# XN11EXXX register map
File version: 1.3
CPU: CM0 r0p0, little endian, no MPU, no FPU, 2 interrupt priority bits
Registers are 32-bit, read-write, reset 0x0 unless marked. A register's access mark holds for its fields unless they carry their own. Offsets are from the block's base; [hi:lo] are bit positions; {n}, {i} and the like mark numbered series.

## PWM — Pulse-Width Modulation
Base 0x4004C000
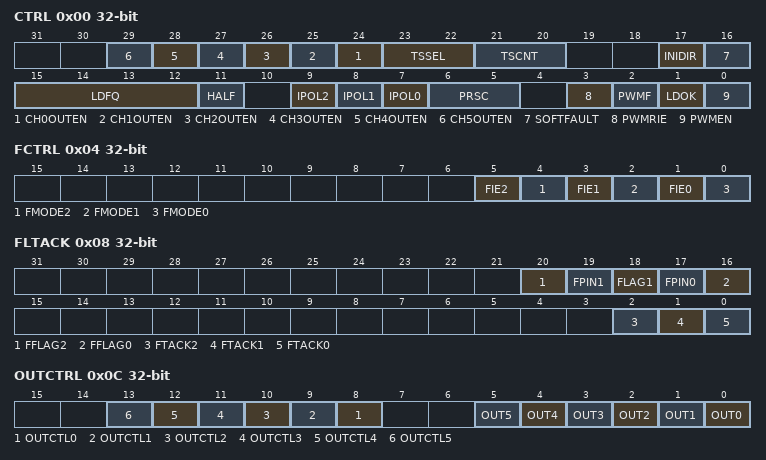
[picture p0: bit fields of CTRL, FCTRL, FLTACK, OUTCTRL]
0x00 CTRL — Control Register
  [n+24] CH{n}OUTEN (n=0..5) — Output a signal when counter register of channel {n} equals to VAL{n}
  [23:22] TSSEL — Trig signal select register
  [21:20] TSCNT — Trig signal output count register
  [17] INIDIR — Select initial count direction in center align mode
  [16] SOFTFAULT — trigger a software fault to the PWM Fault protect mode
  [15:12] LDFQ — select the PWM load frequency
  [11] HALF — Enable half-cycle reloads in Center-Aligned PWM mode
  [9] IPOL2 — Select the PWM value register for the PWM_4 and PWM_5 pins pair in complementary mode.
  [8] IPOL1 — Select the PWM value register for the PWM_2 and PWM_3 pins pair in complementary mode.
  [7] IPOL0 — Select the PWM value register for the PWM_0 and PWM_1 pins pair in complementary mode
  [6:5] PRSC — PWM clock Pre frequency set bit
  [3] PWMRIE — PWMF interrupt control bit
  [2] PWMF — PWM reload flag bit
  [1] LDOK — Load vaule bit
  [0] PWMEN — PWM enable
0x04 FCTRL — Fault Control Register
  [5] FIE2 — Enable the interrupt request generated by the ADC limit fault
  [4] FMODE2 — Select automatic or manual clearing of ADC limit faults
  [3] FIE1 — Enable the interrupt request generated by the Software fault
  [2] FMODE1 — Select automatic or manual clearing of Software faults
  [1] FIE0 — Enable the interrupt request generated by the PWM_FAULT0 pin
  [0] FMODE0 — Select automatic or manual clearing of FAULT0 pin faults
0x08 FLTACK — Fault Status/Acknowledge Register
  [20] FFLAG2 — SOFTFAULT flag
  [19] FPIN1 — ADC limit fault state
  [18] FLAG1 — ADC limit fault flag
  [17] FPIN0 — PWM_FAULT pin state
  [16] FFLAG0 — PWM_FAULT pin fault flag
  [2] FTACK2 — Software error Acknowledge,Writing a Logic 1 to FTACK2 clears FFLAG2
  [1] FTACK1 — ADC limit error Acknowledge,Writing a Logic 1 to FTACK1 clears FFLAG1.
  [0] FTACK0 — PWM_FAULT pin error Acknowledge,Writing a Logic 1 to FTACK0 clears FFLAG0.
0x0C OUTCTRL — Output Control Register
  [n+8] OUTCTL{n} (n=0..5) — Software control enable to PWM_{n}
  [n] OUT{n} (n=0..5) — PWM_{n} control
0x10 CNTR ro — Counter Register
  [15:0] CNT — 16-bit PWM counter
0x14 CMOD — Counter Modulo Register
  [15:0] CM — PWM Counter Modulo value
{0x18+4i} VAL{i} (i=0..5) — Value Register {i}
  [15:0] VAL — PWM value
0x38 DTIM0 reset 0xFFF — Deadtime Register 0
  [15:0] DTIM — deadtime during 0 to 1 transitions
0x3C DTIM1 reset 0xFFF — Deadtime Register 1
  [15:0] DTIM — deadtime during 1 to 0 transitions
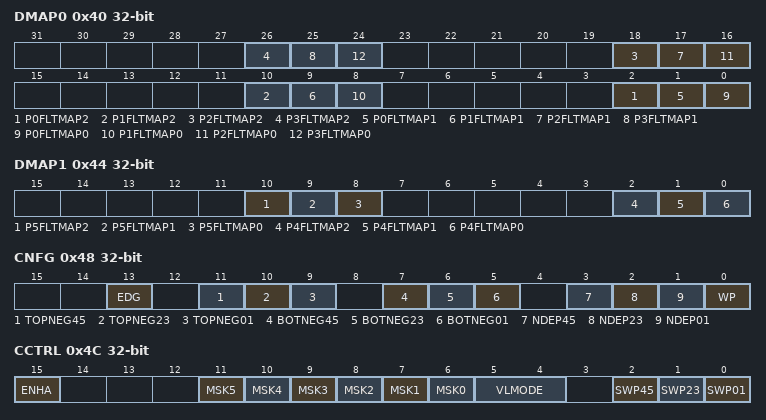
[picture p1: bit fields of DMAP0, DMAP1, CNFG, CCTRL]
0x40 DMAP0 — Disable Mapping Register0
  [8n+2] P{n}FLTMAP2 (n=0..3) — Enables ADC out of limit to protect PWM pin 0 output
  [8n+1] P{n}FLTMAP1 (n=0..3) — Enables Software Fault to protect PWM pin 0 output
  [8n] P{n}FLTMAP0 (n=0..3) — Enables Fault pin 0 to protect PWM pin 0 output
0x44 DMAP1 — Disable Mapping Register1
  [10] P5FLTMAP2 — Enables ADC out of limit to protect PWM pin 0 output
  [9] P5FLTMAP1 — Enables Software Fault to protect PWM pin 0 output
  [8] P5FLTMAP0 — Enables Fault pin 0 to protect PWM pin 0 output
  [2] P4FLTMAP2 — Enables ADC out of limit to protect PWM pin 0 output
  [1] P4FLTMAP1 — Enables Software Fault to protect PWM pin 0 output
  [0] P4FLTMAP0 — Enables Fault pin 0 to protect PWM pin 0 output
0x48 CNFG — Configure Register
  [13] EDG — Edge-Aligned or Center-Aligned wave forms selection
  [11] TOPNEG45 — polarity for the top-side PWMs selection
  [10] TOPNEG23 — polarity for the top-side PWMs selection
  [9] TOPNEG01 — polarity for the top-side PWMs selection
  [7] BOTNEG45 — polarity for the bottom-side PWMs selection
  [6] BOTNEG23 — polarity for the bottom-side PWMs selection
  [5] BOTNEG01 — polarity for the bottom-side PWMs selection
  [3] NDEP45 — independent PWMs or complementary PWM pairs selection
  [2] NDEP23 — independent PWMs or complementary PWM pairs selection
  [1] NDEP01 — independent PWMs or complementary PWM pairs selection
  [0] WP — Enables write-protection for all write-protectable registers
0x4C CCTRL — Channel Control Register
  [15] ENHA — Enable Hardware Acceleration
  [n+6] MSK{n} (n=0..5) — The mask of the PWM logical channel {n}
  [5:4] VLMODE — To be filled
  [2] SWP45 — This bit is write-protected when ENHA is zero
  [1] SWP23 — This bit is write-protected when ENHA is zero
  [0] SWP01 — This bit is write-protected when ENHA is zero
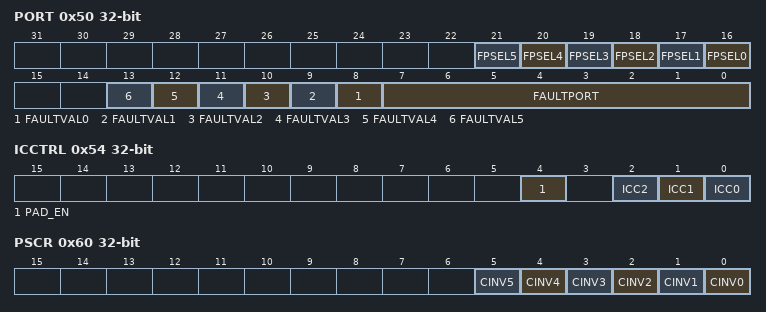
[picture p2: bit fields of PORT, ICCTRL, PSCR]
0x50 PORT
  [n+16] FPSEL{n} (n=0..5) — Enable PWM{n} fault output FAULTVAL{n}
  [n+8] FAULTVAL{n} (n=0..5) — PWM{n} output value when fault happen
  [7:0] FAULTPORT — PWM fault input value
0x54 ICCTRL — Internal Correction Control Register
  [4] PAD_EN — PWM pad output enable
  [2] ICC2 — Select VAL4 or VAL5 to controls PWM4/PWM5 pair.
  [1] ICC1 — Select VAL2 or VAL3 to controls PWM2/PWM3 pair.
  [0] ICC0 — Select VAL0 or VAL1 to controls PWM0/PWM1 pair.
0x60 PSCR — Polarity Invert control Register
  [n] CINV{n} (n=0..5) — This bit controls the polarity of PWM compare output {n}
0x64 CNTRINI wo — Counter Init Register
  [15:0] INITVAL — PWM counter start value
